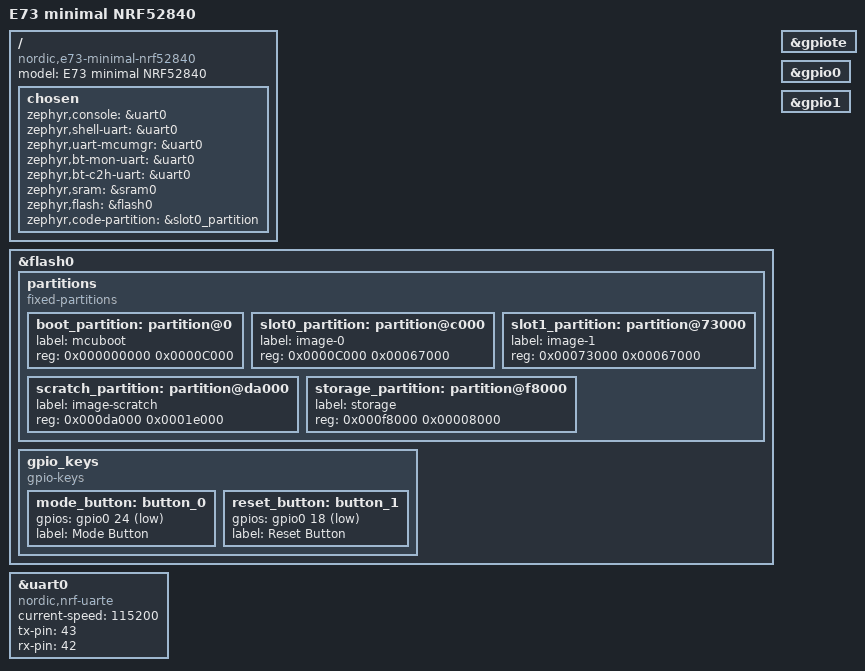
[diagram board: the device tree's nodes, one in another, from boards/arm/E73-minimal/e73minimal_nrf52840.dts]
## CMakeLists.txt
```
# SPDX-License-Identifier: Apache-2.0

cmake_minimum_required(VERSION 3.20.0)
set(BOARD_ROOT ${CMAKE_CURRENT_LIST_DIR})
find_package(Zephyr REQUIRED HINTS $ENV{ZEPHYR_BASE})
project(ncp)

target_sources( app
    PRIVATE
        src/main.c
)

include(${ZEPHYR_BASE}/samples/net/common/common.cmake)

set(gen_dir ${ZEPHYR_BINARY_DIR}/include/generated/)
```

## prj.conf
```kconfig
CONFIG_NETWORKING=y
CONFIG_NET_L2_OPENTHREAD=y

# Disable certain parts of Zephyr IPv6 stack
CONFIG_NET_IPV6_NBR_CACHE=n
CONFIG_NET_IPV6_MLD=n

# Logging
CONFIG_LOG=y
CONFIG_LOG_MAX_LEVEL=1
CONFIG_LOG_MODE_MINIMAL=n
CONFIG_LOG_BACKEND_SPINEL=y
CONFIG_LOG_BACKEND_RTT=y
CONFIG_LOG_BACKEND_UART=n
CONFIG_BOOT_BANNER=n
CONFIG_MCUBOOT_SIGNATURE_KEY_FILE="bootloader/mcuboot/root-ec-p256.pem"
# Kernel options
CONFIG_MAIN_STACK_SIZE=2048
CONFIG_INIT_STACKS=y

# Increase logging thread stack size due to Spinel backend needs
CONFIG_LOG_PROCESS_THREAD_STACK_SIZE=2048

# Set OpenThread NCP architecture
CONFIG_OPENTHREAD_COPROCESSOR=y
CONFIG_OPENTHREAD_COPROCESSOR_NCP=y

# Add features required for NCP
CONFIG_OPENTHREAD_DIAG=y
CONFIG_OPENTHREAD_DHCP6_SERVER=y
CONFIG_OPENTHREAD_COMMISSIONER=y
CONFIG_OPENTHREAD_BORDER_AGENT=y
CONFIG_OPENTHREAD_BORDER_ROUTER=y
CONFIG_OPENTHREAD_UDP_FORWARD=y
CONFIG_OPENTHREAD_ENABLE_SERVICE=y
```

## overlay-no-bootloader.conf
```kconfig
CONFIG_FLASH=n
CONFIG_IMG_MANAGER=n
CONFIG_FLASH_PAGE_LAYOUT=n
CONFIG_BOOTLOADER_MCUBOOT=n
```

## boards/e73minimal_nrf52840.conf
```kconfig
# FLASH
CONFIG_FLASH=y
CONFIG_FLASH_PAGE_LAYOUT=y
CONFIG_SOC_FLASH_NRF=y


CONFIG_BOOTLOADER_MCUBOOT=y
CONFIG_REBOOT=y
CONFIG_IMG_MANAGER=y
CONFIG_IMG_BLOCK_BUF_SIZE=2048
CONFIG_SETTINGS_NVS=y
CONFIG_NVS=y
```

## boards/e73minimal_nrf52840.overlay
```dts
/*
 * Copyright (c) 2021 Telink Semiconductor
 *
 * SPDX-License-Identifier: Apache-2.0
 */

/ {
	chosen {
		zephyr,ot-uart = &uart0;
	};
};
```

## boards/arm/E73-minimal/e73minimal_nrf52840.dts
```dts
/*
 * Copyright (c) 2018 Nordic Semiconductor ASA
 * Copyright (c) 2017 Linaro Limited
 *
 * SPDX-License-Identifier: Apache-2.0
 */

/dts-v1/;
#include <nordic/nrf52840_qiaa.dtsi>

/ {
	model = "E73 minimal NRF52840";
	compatible = "nordic,e73-minimal-nrf52840";

	chosen {
		zephyr,console = &uart0;
		zephyr,shell-uart = &uart0;
		zephyr,uart-mcumgr = &uart0;
		zephyr,bt-mon-uart = &uart0;
		zephyr,bt-c2h-uart = &uart0;
		zephyr,sram = &sram0;
		zephyr,flash = &flash0;
		zephyr,code-partition = &slot0_partition;
	};




};

&flash0 {
	partitions {
		compatible = "fixed-partitions";
		#address-cells = <1>;
		#size-cells = <1>;

		boot_partition: partition@0 {
			label = "mcuboot";
			reg = <0x000000000 0x0000C000>;
		};
		slot0_partition: partition@c000 {
			label = "image-0";
			reg = <0x0000C000 0x00067000>;
		};
		slot1_partition: partition@73000 {
			label = "image-1";
			reg = <0x00073000 0x00067000>;
		};
		scratch_partition: partition@da000 {
			label = "image-scratch";
			reg = <0x000da000 0x0001e000>;
		};

		/*
		 * The flash starting at 0x000f8000 and ending at
		 * 0x000fffff is reserved for use by the application.
		 */

		/*
		 * Storage partition will be used by FCB/LittleFS/NVS
		 * if enabled.
		 */
		storage_partition: partition@f8000 {
			label = "storage";
			reg = <0x000f8000 0x00008000>;
		};
	};
	gpio_keys {
		compatible = "gpio-keys";
		mode_button: button_0 {
			gpios = <&gpio0 24 (GPIO_PULL_UP | GPIO_ACTIVE_LOW)>;
			label = "Mode Button";
		};

		reset_button: button_1 {
				gpios = <&gpio0 18 (GPIO_PULL_UP | GPIO_ACTIVE_LOW)>;
				label = "Reset Button";
		};
	 
	};
};

&gpiote {
	status = "okay";
};

&gpio0 {
	status = "okay";
};

&gpio1 {
	status = "okay";
};

&uart0 {
	compatible = "nordic,nrf-uarte";
	status = "okay";
	current-speed = <115200>;
	tx-pin = <43>;
	rx-pin = <42>;
};
```

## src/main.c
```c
/* main.c - OpenThread NCP */

/*
 * Copyright (c) 2020 Tridonic GmbH & Co KG
 *
 * SPDX-License-Identifier: Apache-2.0
 */

#include <logging/log.h>
LOG_MODULE_REGISTER(ot_br, LOG_LEVEL_DBG);

#include <zephyr.h>
#include <usb/usb_device.h>
#include <drivers/uart.h>

#define APP_BANNER "***** OpenThread NCP on Zephyr %s *****"

void main(void) {
#if defined(CONFIG_OPENTHREAD_COPROCESSOR_SPINEL_ON_UART_ACM)
	const struct device *dev;
	uint32_t baudrate = 0U;
	int ret;

	dev = device_get_binding(
		CONFIG_OPENTHREAD_COPROCESSOR_SPINEL_ON_UART_DEV_NAME);
	if (!dev) {
		LOG_ERR("UART device not found");
		return;
	}

	ret = usb_enable(NULL);
	if (ret != 0) {
		LOG_ERR("Failed to enable USB");
		return;
	}

	LOG_INF("Wait for host to settle");
	k_sleep(K_SECONDS(1));

	ret = uart_line_ctrl_get(dev, UART_LINE_CTRL_BAUD_RATE, &baudrate);
	if (ret) {
		LOG_WRN("Failed to get baudrate, ret code %d", ret);
	} else {
		LOG_INF("Baudrate detected: %d", baudrate);
	}
#endif /* CONFIG_OPENTHREAD_COPROCESSOR_SPINEL_ON_UART_ACM */

	LOG_INF(APP_BANNER, CONFIG_NET_SAMPLE_APPLICATION_VERSION);
}
```
